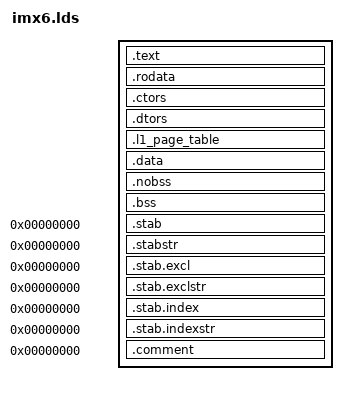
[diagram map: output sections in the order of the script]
OUTPUT_FORMAT("elf32-littlearm", "elf32-littlearm", "elf32-littlearm")
OUTPUT_ARCH(arm)

SECTIONS
{
    . = 0x80300000;

    . = ALIGN(4);
    .text :
    {
        *(.vectors)
        *(.text)
        *(.text.*)

        /* section information for finsh shell */
        . = ALIGN(4);
        __fsymtab_start = .;
        KEEP(*(FSymTab))
        __fsymtab_end = .;
        . = ALIGN(4);
        __vsymtab_start = .;
        KEEP(*(VSymTab))
        __vsymtab_end = .;

        /* section information for init */
       . = ALIGN(4);
        __rt_init_start = .;
        KEEP(*(SORT(.rti_fn*)))
        __rt_init_end = .;

        /* section information for modules */
        . = ALIGN(4);
        __rtmsymtab_start = .;
        KEEP(*(RTMSymTab))
        __rtmsymtab_end = .;
    }

    . = ALIGN(4);
    .rodata   : { *(.rodata) *(.rodata.*) }

    . = ALIGN(4);
    .ctors :
    {
        PROVIDE(__ctors_start__ = .);
        KEEP(*(SORT(.ctors.*)))
        KEEP(*(.ctors))
        PROVIDE(__ctors_end__ = .);
    }

    .dtors :
    {
        PROVIDE(__dtors_start__ = .);
        KEEP(*(SORT(.dtors.*)))
        KEEP(*(.dtors))
        PROVIDE(__dtors_end__ = .);
    }

    . = ALIGN(16 * 1024);
    .l1_page_table :
    {
        __l1_page_table_start = .;
        . += 16K;
    }

    . = ALIGN(4);
    .data :
    {
        *(.data)
        *(.data.*)
    }

    . = ALIGN(4);
    .nobss : { *(.nobss) }

    . = ALIGN(4);
    __bss_start = .;
    .bss : { *(.bss) *(.bss.*) *(COMMON) }
    __bss_end = .;

    /* Stabs debugging sections.  */
    .stab 0 : { *(.stab) }
    .stabstr 0 : { *(.stabstr) }
    .stab.excl 0 : { *(.stab.excl) }
    .stab.exclstr 0 : { *(.stab.exclstr) }
    .stab.index 0 : { *(.stab.index) }
    .stab.indexstr 0 : { *(.stab.indexstr) }
    .comment 0 : { *(.comment) }

    _end = .;
}
